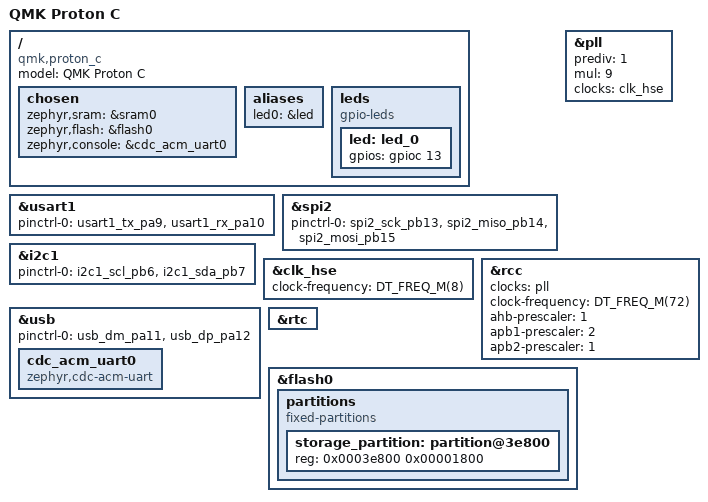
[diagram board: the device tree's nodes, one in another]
/*
 * Copyright (c) 2020 The ZMK Contributors
 *
 * SPDX-License-Identifier: MIT
 */

/dts-v1/;
#include <st/f3/stm32f303Xc.dtsi>
#include <st/f3/stm32f303c(b-c)tx-pinctrl.dtsi>
#include "arduino_pro_micro_pins.dtsi"

/ {
    model = "QMK Proton C";
    compatible = "qmk,proton_c", "st,stm32f303";

    chosen {
        zephyr,sram = &sram0;
        zephyr,flash = &flash0;
        zephyr,console = &cdc_acm_uart0;
    };

    aliases {
        led0 = &led;
    };

    leds {
        compatible = "gpio-leds";
        led: led_0 {
            gpios = <&gpioc 13 GPIO_ACTIVE_HIGH>;
        };
    };
};

&usart1 {
    pinctrl-0 = <&usart1_tx_pa9 &usart1_rx_pa10>;
    pinctrl-names = "default";
};

&spi2 {
    pinctrl-0 = <&spi2_sck_pb13 &spi2_miso_pb14 &spi2_mosi_pb15>;
    pinctrl-names = "default";
};

&i2c1 {
    pinctrl-0 = <&i2c1_scl_pb6 &i2c1_sda_pb7>;
    pinctrl-names = "default";
};

&clk_hse {
    status = "okay";
    clock-frequency = <DT_FREQ_M(8)>;
};

&pll {
    prediv = <1>;
    mul = <9>;
    clocks = <&clk_hse>;
    status = "okay";
};

&rcc {
    clocks = <&pll>;
    clock-frequency = <DT_FREQ_M(72)>;
    ahb-prescaler = <1>;
    apb1-prescaler = <2>;
    apb2-prescaler = <1>;
};

&usb {
    pinctrl-0 = <&usb_dm_pa11 &usb_dp_pa12>;
    pinctrl-names = "default";
    status = "okay";
    cdc_acm_uart0: cdc_acm_uart0 {
        compatible = "zephyr,cdc-acm-uart";
    };
};

&rtc {
    status = "okay";
};

&flash0 {
    /*
     * For more information, see:
     * http://docs.zephyrproject.org/latest/guides/dts/index.html#flash-partitions
     */
    partitions {
        compatible = "fixed-partitions";
        #address-cells = <1>;
        #size-cells = <1>;

        /* Set 6Kb of storage at the end of the 256Kb of flash */
        storage_partition: partition@3e800 {
            reg = <0x0003e800 0x00001800>;
        };
    };
};
